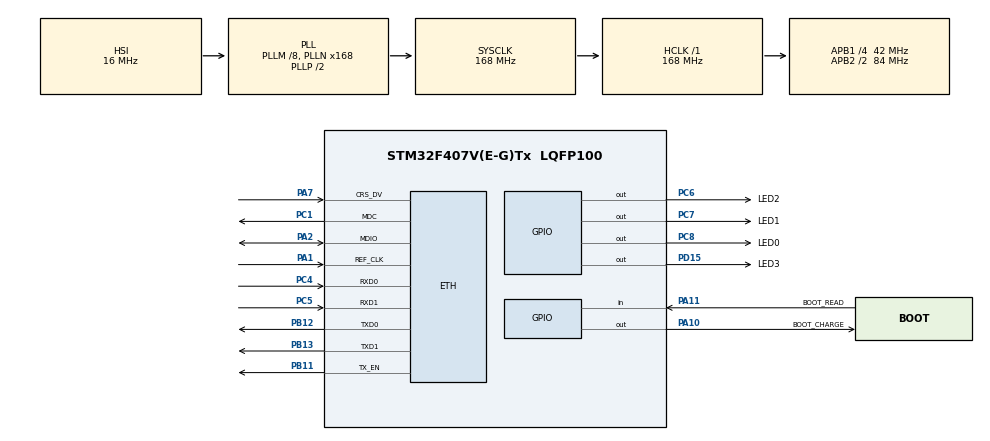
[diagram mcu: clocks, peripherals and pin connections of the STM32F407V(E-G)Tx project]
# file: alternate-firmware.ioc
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ETH.MediaInterface=HAL_ETH_RMII_MODE
ETH.PHY_DUPLEX_STATUS=0x0010
ETH.PHY_ISFR_INT4=0x0010
ETH.PHY_Name_RMII=LAN8742A_PHY_ADDRESS
ETH.PHY_SPEED_STATUS=0x0004
ETH.PHY_SR=0x1F
ETH.PhyAddress=0
FREERTOS.HEAP_NUMBER=4
FREERTOS.Tasks01=defaultTask,1,256,StartDefaultTask,Default,NULL,Dynamic,NULL,NULL;tcpTask,0,512,StartTCPTask,Default,NULL,Dynamic,NULL,NULL
FREERTOS.configMAX_PRIORITIES=16
FREERTOS.configMINIMAL_STACK_SIZE=128
FREERTOS.configTOTAL_HEAP_SIZE=0x6000
FREERTOS.configUSE_NEWLIB_REENTRANT=1
LWIP.BSP.number=1
LWIP.CMSIS_VERSION-Enabled=1
LWIP.GATEWAY_ADDRESS=192.168.050.001
LWIP.IP_ADDRESS=192.168.050.010
LWIP.LWIP_DHCP=0
LWIP.LWIP_HTTPD=0
LWIP.LWIP_SO_RCVTIMEO=1
LWIP.LWIP_STATS=1
LWIP.LWIP_TFTP=0
LWIP.MEMP_NUM_NETBUF=8
LWIP.MEMP_NUM_NETCONN=8
LWIP.MEMP_NUM_TCP_PCB=8
LWIP.NETMASK_ADDRESS=255.255.255.000
LWIP.Version=v2.1.2_Cube
LWIP0.BSP.STBoard=false
LWIP0.BSP.api=BSP_COMPONENT_DRIVER
LWIP0.BSP.component=LAN8742
LWIP0.BSP.instance=LAN8742
LWIP0.BSP.name=Driver_PHY
LWIP0.BSP.semaphore=S_LAN8742
LWIP0.BSP.solution=LAN8742
Mcu.Family=STM32F4
Mcu.Name=STM32F407V(E-G)Tx
Mcu.Package=LQFP100
NVIC.ETH_IRQn=true\:5\:0\:false\:false\:true\:true\:false\:true\:true
NVIC.PriorityGroup=NVIC_PRIORITYGROUP_4
NVIC.TIM6_DAC_IRQn=true\:15\:0\:false\:false\:true\:false\:false\:true\:true
NVIC.TimeBase=TIM6_DAC_IRQn
NVIC.TimeBaseIP=TIM6
PA1.Mode=RMII
PA1.Signal=ETH_REF_CLK
PA10.GPIO_Label=BOOT_CHARGE
PA10.Signal=GPIO_Output
PA11.GPIO_Label=BOOT_READ
PA11.Signal=GPIO_Input
PA13.Mode=Trace_Asynchronous_SW
PA13.Signal=SYS_JTMS-SWDIO
PA14.Mode=Trace_Asynchronous_SW
PA14.Signal=SYS_JTCK-SWCLK
PA2.Mode=RMII
PA2.Signal=ETH_MDIO
PA7.Mode=RMII
PA7.Signal=ETH_CRS_DV
PB11.Mode=RMII
PB11.Signal=ETH_TX_EN
PB12.Mode=RMII
PB12.Signal=ETH_TXD0
PB13.Mode=RMII
PB13.Signal=ETH_TXD1
PB3.Mode=Trace_Asynchronous_SW
PB3.Signal=SYS_JTDO-SWO
PC1.Mode=RMII
PC1.Signal=ETH_MDC
PC4.Mode=RMII
PC4.Signal=ETH_RXD0
PC5.Mode=RMII
PC5.Signal=ETH_RXD1
PC6.GPIO_Label=LED2
PC6.Signal=GPIO_Output
PC7.GPIO_Label=LED1
PC7.Signal=GPIO_Output
PC8.GPIO_Label=LED0
PC8.Signal=GPIO_Output
PD15.GPIO_Label=LED3
PD15.Signal=GPIO_Output
PH0-OSC_IN.Mode=HSE-External-Clock-Source
PH0-OSC_IN.Signal=RCC_OSC_IN
PH1-OSC_OUT.Mode=HSE-External-Clock-Source
PH1-OSC_OUT.Signal=RCC_OSC_OUT
ProjectManager.HeapSize=0x10000
ProjectManager.StackSize=0x400
ProjectManager.TargetToolchain=STM32CubeIDE
RCC.48MHZClocksFreq_Value=84000000
RCC.AHBFreq_Value=168000000
RCC.APB1CLKDivider=RCC_HCLK_DIV4
RCC.APB1Freq_Value=42000000
RCC.APB1TimFreq_Value=84000000
RCC.APB2CLKDivider=RCC_HCLK_DIV2
RCC.APB2Freq_Value=84000000
RCC.APB2TimFreq_Value=168000000
RCC.CortexFreq_Value=168000000
RCC.HCLKFreq_Value=168000000
RCC.HSE_VALUE=50000000
RCC.HSI_VALUE=16000000
RCC.LSE_VALUE=32768
RCC.PLLM=8
RCC.PLLN=168
RCC.SYSCLKFreq_VALUE=168000000
RCC.SYSCLKSource=RCC_SYSCLKSOURCE_PLLCLK
RCC.VCOOutputFreq_Value=336000000
VP_FREERTOS_VS_CMSIS_V1.Mode=CMSIS_V1
VP_LWIP_VS_Enabled.Mode=Enabled
VP_RTC_VS_RTC_Activate.Mode=RTC_Enabled
VP_SYS_VS_tim6.Mode=TIM6
board=custom

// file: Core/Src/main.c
/* USER CODE BEGIN Header */
/**
 ******************************************************************************
 * @file           : main.c
 * @brief          : Main program body
 ******************************************************************************
 * @attention
 *
 * Copyright (c) 2023 STMicroelectronics.
 * All rights reserved.
 *
 * This software is licensed under terms that can be found in the LICENSE file
 * in the root directory of this software component.
 * If no LICENSE file comes with this software, it is provided AS-IS.
 *
 ******************************************************************************
 */
/* USER CODE END Header */
#include "main.h"
#include "cmsis_os.h"
#include "lwip.h"

/* USER CODE BEGIN Includes */
#include "tcpserver.h"
/* USER CODE END Includes */

RTC_HandleTypeDef hrtc;

osThreadId defaultTaskHandle;
osThreadId tcpTaskHandle;
/* USER CODE BEGIN PV */
osThreadId tcpTaskHandle;
/* USER CODE END PV */

void SystemClock_Config(void);
static void MX_GPIO_Init(void);
static void MX_RTC_Init(void);
void StartDefaultTask(void const * argument);
void StartTCPTask(void const * argument);

/* USER CODE BEGIN PFP */
extern void tcpdev_recv_cmd();
/* USER CODE END PFP */

int main(void)
{

  /* MCU Configuration--------------------------------------------------------*/

  /* Reset of all peripherals, Initializes the Flash interface and the Systick. */
  HAL_Init();

  /* Configure the system clock */
  SystemClock_Config();

  /* Initialize all configured peripherals */
  MX_GPIO_Init();
  MX_RTC_Init();

  /* Create the thread(s) */
  /* definition and creation of defaultTask */
  osThreadDef(defaultTask, StartDefaultTask, osPriorityAboveNormal, 0, 256);
  defaultTaskHandle = osThreadCreate(osThread(defaultTask), NULL);

  /* definition and creation of tcpTask */
  osThreadDef(tcpTask, StartTCPTask, osPriorityNormal, 0, 512);
  tcpTaskHandle = osThreadCreate(osThread(tcpTask), NULL);

  /* Start scheduler */
  osKernelStart();

  /* We should never get here as control is now taken by the scheduler */
  /* Infinite loop */
	while (1) {

	}
}

void SystemClock_Config(void)
{
  RCC_OscInitTypeDef RCC_OscInitStruct = {0};
  RCC_ClkInitTypeDef RCC_ClkInitStruct = {0};

  /** Configure the main internal regulator output voltage
  */
  __HAL_RCC_PWR_CLK_ENABLE();
  __HAL_PWR_VOLTAGESCALING_CONFIG(PWR_REGULATOR_VOLTAGE_SCALE1);

  /** Initializes the RCC Oscillators according to the specified parameters
  * in the RCC_OscInitTypeDef structure.
  */
  RCC_OscInitStruct.OscillatorType = RCC_OSCILLATORTYPE_HSI|RCC_OSCILLATORTYPE_LSI;
  RCC_OscInitStruct.HSIState = RCC_HSI_ON;
  RCC_OscInitStruct.HSICalibrationValue = RCC_HSICALIBRATION_DEFAULT;
  RCC_OscInitStruct.LSIState = RCC_LSI_ON;
  RCC_OscInitStruct.PLL.PLLState = RCC_PLL_ON;
  RCC_OscInitStruct.PLL.PLLSource = RCC_PLLSOURCE_HSI;
  RCC_OscInitStruct.PLL.PLLM = 8;
  RCC_OscInitStruct.PLL.PLLN = 168;
  RCC_OscInitStruct.PLL.PLLP = RCC_PLLP_DIV2;
  RCC_OscInitStruct.PLL.PLLQ = 4;
  if (HAL_RCC_OscConfig(&RCC_OscInitStruct) != HAL_OK)
  {
    Error_Handler();
  }

  /** Initializes the CPU, AHB and APB buses clocks
  */
  RCC_ClkInitStruct.ClockType = RCC_CLOCKTYPE_HCLK|RCC_CLOCKTYPE_SYSCLK
                              |RCC_CLOCKTYPE_PCLK1|RCC_CLOCKTYPE_PCLK2;
  RCC_ClkInitStruct.SYSCLKSource = RCC_SYSCLKSOURCE_PLLCLK;
  RCC_ClkInitStruct.AHBCLKDivider = RCC_SYSCLK_DIV1;
  RCC_ClkInitStruct.APB1CLKDivider = RCC_HCLK_DIV4;
  RCC_ClkInitStruct.APB2CLKDivider = RCC_HCLK_DIV2;

  if (HAL_RCC_ClockConfig(&RCC_ClkInitStruct, FLASH_LATENCY_5) != HAL_OK)
  {
    Error_Handler();
  }
}

static void MX_RTC_Init(void)
{

  /** Initialize RTC Only
  */
  hrtc.Instance = RTC;
  hrtc.Init.HourFormat = RTC_HOURFORMAT_24;
  hrtc.Init.AsynchPrediv = 127;
  hrtc.Init.SynchPrediv = 255;
  hrtc.Init.OutPut = RTC_OUTPUT_DISABLE;
  hrtc.Init.OutPutPolarity = RTC_OUTPUT_POLARITY_HIGH;
  hrtc.Init.OutPutType = RTC_OUTPUT_TYPE_OPENDRAIN;
  if (HAL_RTC_Init(&hrtc) != HAL_OK)
  {
    Error_Handler();
  }

}

static void MX_GPIO_Init(void)
{
  GPIO_InitTypeDef GPIO_InitStruct = {0};

  /* GPIO Ports Clock Enable */
  __HAL_RCC_GPIOH_CLK_ENABLE();
  __HAL_RCC_GPIOC_CLK_ENABLE();
  __HAL_RCC_GPIOA_CLK_ENABLE();
  __HAL_RCC_GPIOB_CLK_ENABLE();
  __HAL_RCC_GPIOD_CLK_ENABLE();

  /*Configure GPIO pin Output Level */
  HAL_GPIO_WritePin(LED3_GPIO_Port, LED3_Pin, GPIO_PIN_RESET);

  /*Configure GPIO pin Output Level */
  HAL_GPIO_WritePin(GPIOC, LED2_Pin|LED1_Pin|LED0_Pin, GPIO_PIN_RESET);

  /*Configure GPIO pin Output Level */
  HAL_GPIO_WritePin(BOOT_CHARGE_GPIO_Port, BOOT_CHARGE_Pin, GPIO_PIN_RESET);

  /*Configure GPIO pin : LED3_Pin */
  GPIO_InitStruct.Pin = LED3_Pin;
  GPIO_InitStruct.Mode = GPIO_MODE_OUTPUT_PP;
  GPIO_InitStruct.Pull = GPIO_NOPULL;
  GPIO_InitStruct.Speed = GPIO_SPEED_FREQ_LOW;
  HAL_GPIO_Init(LED3_GPIO_Port, &GPIO_InitStruct);

  /*Configure GPIO pins : LED2_Pin LED1_Pin LED0_Pin */
  GPIO_InitStruct.Pin = LED2_Pin|LED1_Pin|LED0_Pin;
  GPIO_InitStruct.Mode = GPIO_MODE_OUTPUT_PP;
  GPIO_InitStruct.Pull = GPIO_NOPULL;
  GPIO_InitStruct.Speed = GPIO_SPEED_FREQ_LOW;
  HAL_GPIO_Init(GPIOC, &GPIO_InitStruct);

  /*Configure GPIO pin : BOOT_CHARGE_Pin */
  GPIO_InitStruct.Pin = BOOT_CHARGE_Pin;
  GPIO_InitStruct.Mode = GPIO_MODE_OUTPUT_PP;
  GPIO_InitStruct.Pull = GPIO_NOPULL;
  GPIO_InitStruct.Speed = GPIO_SPEED_FREQ_LOW;
  HAL_GPIO_Init(BOOT_CHARGE_GPIO_Port, &GPIO_InitStruct);

  /*Configure GPIO pin : BOOT_READ_Pin */
  GPIO_InitStruct.Pin = BOOT_READ_Pin;
  GPIO_InitStruct.Mode = GPIO_MODE_INPUT;
  GPIO_InitStruct.Pull = GPIO_NOPULL;
  HAL_GPIO_Init(BOOT_READ_GPIO_Port, &GPIO_InitStruct);

}

/* USER CODE BEGIN 4 */
/**
 * @brief  Function implementing the TCPTask thread.
 * @param  argument: Not used
 * @retval None
 */
/* USER CODE END Header_StartTCPTask */

/* USER CODE END 4 */

void StartDefaultTask(void const * argument)
{
  /* init code for LWIP */
  MX_LWIP_Init();
  /* USER CODE BEGIN 5 */

	//MX_LWIP_Init();

	//tcpwriter_init();

	/* Infinite loop */
	for (;;) {
		/*
		 *  Heartbeat LED0
		 */
		//osDelay(1);
		HAL_GPIO_TogglePin(LED0_GPIO_Port, LED0_Pin);
		osDelay(500);
	}
  /* USER CODE END 5 */
}

void StartTCPTask(void const * argument)
{
  /* USER CODE BEGIN StartTCPTask */

	server_init();

  /* Infinite loop */
  for(;;)
  {
    osDelay(1);
  }
  /* USER CODE END StartTCPTask */
}

void HAL_TIM_PeriodElapsedCallback(TIM_HandleTypeDef *htim)
{
  if (htim->Instance == TIM6) {
    HAL_IncTick();
  }
}

void Error_Handler(void)
{
	__disable_irq();
	while (1) {
	}
}
